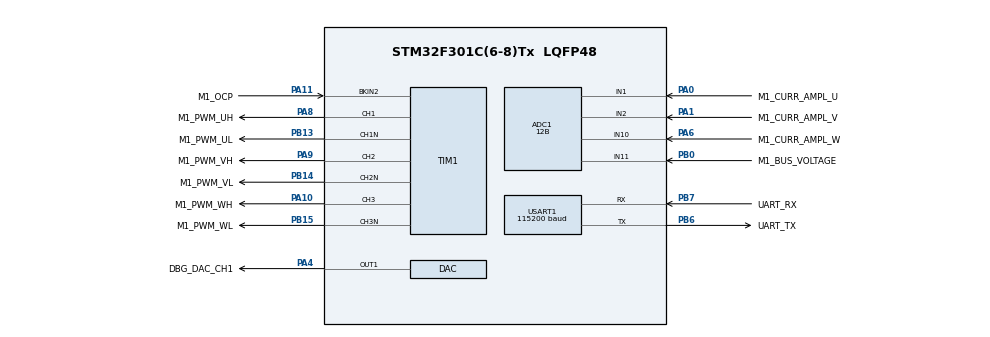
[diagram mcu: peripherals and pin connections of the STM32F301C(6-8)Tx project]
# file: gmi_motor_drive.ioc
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ADC1.Channel-1\#ChannelRegularConversion=ADC_CHANNEL_11
ADC1.Channel-IN1-Single-Ended=ADC_CHANNEL_1
ADC1.Channel-IN10-Single-Ended=ADC_CHANNEL_10
ADC1.Channel-IN11-Single-Ended=ADC_CHANNEL_11
ADC1.Channel-IN2-Single-Ended=ADC_CHANNEL_2
ADC1.ClockPrescaler=ADC_CLOCK_SYNC_PCLK_DIV1
ADC1.ContinuousConvMode=DISABLE
ADC1.DMAContinuousRequests=DISABLE
ADC1.DataAlign=ADC_DATAALIGN_LEFT
ADC1.DiscontinuousConvMode=DISABLE
ADC1.EOCSelection=ADC_EOC_SINGLE_CONV
ADC1.EnableAnalogWatchDog1=false
ADC1.EnableAnalogWatchDog2=false
ADC1.EnableAnalogWatchDog3=false
ADC1.EnableInjectedConversion=ENABLE
ADC1.EnableRegularConversion=ENABLE
ADC1.ExternalTrigConv=ADC_SOFTWARE_START
ADC1.ExternalTrigConvEdge=ADC_EXTERNALTRIGCONVEDGE_NONE
ADC1.ExternalTrigInjecConv=ADC_EXTERNALTRIGINJECCONV_T1_TRGO
ADC1.ExternalTrigInjecConvEdge=ADC_EXTERNALTRIGINJECCONV_EDGE_RISING
ADC1.InjNumberOfConversion=3
ADC1.InjectedChannel-1\#ChannelInjectedConversion=ADC_CHANNEL_1
ADC1.InjectedChannel-2\#ChannelInjectedConversion=ADC_CHANNEL_2
ADC1.InjectedChannel-3\#ChannelInjectedConversion=ADC_CHANNEL_10
ADC1.InjectedConvMode=None
ADC1.InjectedOffset-1\#ChannelInjectedConversion=0
ADC1.InjectedOffset-2\#ChannelInjectedConversion=0
ADC1.InjectedOffset-3\#ChannelInjectedConversion=0
ADC1.InjectedOffsetNumber-1\#ChannelInjectedConversion=ADC_OFFSET_NONE
ADC1.InjectedOffsetNumber-2\#ChannelInjectedConversion=ADC_OFFSET_NONE
ADC1.InjectedOffsetNumber-3\#ChannelInjectedConversion=ADC_OFFSET_NONE
ADC1.InjectedRank-1\#ChannelInjectedConversion=1
ADC1.InjectedRank-2\#ChannelInjectedConversion=2
ADC1.InjectedRank-3\#ChannelInjectedConversion=3
ADC1.InjectedSamplingTime-1\#ChannelInjectedConversion=ADC_SAMPLETIME_19CYCLES_5
ADC1.InjectedSamplingTime-2\#ChannelInjectedConversion=ADC_SAMPLETIME_19CYCLES_5
ADC1.InjectedSamplingTime-3\#ChannelInjectedConversion=ADC_SAMPLETIME_19CYCLES_5
ADC1.LowPowerAutoWait=DISABLE
ADC1.NbrOfConversion=1
ADC1.Offset-1\#ChannelRegularConversion=0
ADC1.OffsetNumber-1\#ChannelRegularConversion=ADC_OFFSET_NONE
ADC1.Overrun=ADC_OVR_DATA_PRESERVED
ADC1.QueueInjectedContext=ENABLE
ADC1.Rank-1\#ChannelRegularConversion=1
ADC1.Resolution=ADC_RESOLUTION_12B
ADC1.SamplingTime-1\#ChannelRegularConversion=ADC_SAMPLETIME_61CYCLES_5
ADC1.ScanConvMode=ADC_SCAN_ENABLE
ADC1.SubFamily=STM32F301x8
ADC1.master=1
DAC.DAC_OutputBuffer-DAC_OUT1=DAC_OUTPUTBUFFER_DISABLE
DAC.DAC_Trigger-DAC_OUT1=DAC_TRIGGER_SOFTWARE
DAC.WaveGeneration-DAC_OUT1=DISABLE
ExtraMW=MotorControl
ExtraMW.MotorControl.Config=MotorControl
ExtraMW.MotorControl.Mode=MotorControl
ExtraMW.MotorControl.Root=MCSDK_v5.4.4-Full/MotorControl
ExtraMW.MotorControl.Template=templates
Mcu.Family=STM32F3
Mcu.Name=STM32F301C(6-8)Tx
Mcu.Package=LQFP48
MotorControl.ADC_1_PERIPH=ADC1
MotorControl.ADC_2_PERIPH=ADC2
MotorControl.ADC_AHBPERIPH=RCC_AHBPeriph_ADC12
MotorControl.ADC_CLOCK_WB_DIV=1
MotorControl.ADC_CLOCK_WB_FREQ=64
MotorControl.ADC_PERIPH=ADC1
MotorControl.ADC_REFERENCE_VOLTAGE=3.30
MotorControl.ALIGNMENT_ANGLE_DEG=90
MotorControl.ALIGNMENT_DURATION=700
MotorControl.AMPLIFICATION_GAIN=7.33
MotorControl.ANGC={0,0,0,0,0,0,0,0}
MotorControl.BEMF_CONSISTENCY_GAIN=64
MotorControl.BEMF_CONSISTENCY_TOL=64
MotorControl.BKIN1_FILTER=0
MotorControl.BKIN2_FILTER=7
MotorControl.BKIN2_MODE=EXT_MODE
MotorControl.BKIN_MODE=NONE
MotorControl.BOARD=CUSTOM
MotorControl.BRKIN2_GPIO_AF=GPIO_AF_2
MotorControl.BRKIN_GPIO_AF=GPIO_AF_12
MotorControl.BUS_VOLTAGE_READING=true
MotorControl.CCMRAM_ENABLED=false
MotorControl.CLOCK_FREQUENCY=CPU_CLK_64_MHZ
MotorControl.CLOCK_SOURCE=INTERNAL
MotorControl.CONSTANT1_D=1347084
MotorControl.CONSTANT1_Q=2435957
MotorControl.CONSTANT2_QD=9081
MotorControl.CORD_BEMF_CONSISTENCY_GAIN=64
MotorControl.CORD_BEMF_CONSISTENCY_TOL=64
MotorControl.CORD_F1=16384
MotorControl.CORD_F2=256
MotorControl.CORD_FIFO_DEPTH_01HZ=64
MotorControl.CORD_FIFO_DEPTH_DPP=64
MotorControl.CORD_GAIN1=-24527
MotorControl.CORD_GAIN2=30710
MotorControl.CORD_MAX_ACCEL_DPPP=301
MotorControl.CORD_MEAS_ERRORS_BEFORE_FAULTS=3
MotorControl.CORD_VARIANCE_THRESHOLD=4
MotorControl.CPU_CLK_64_MHZ=true
MotorControl.CTRBDID=0
MotorControl.CUBE_MX_VER=5.6.1
MotorControl.CURRENT_READING_TOPOLOGY=THREE_SHUNT
MotorControl.CURR_SAMPLING_TIME=61
MotorControl.DAC_EMULATED=false
MotorControl.DAC_FUNCTIONALITY=true
MotorControl.DAC_TIMER_CH1_GPIO_PIN=LL_GPIO_PIN_4
MotorControl.DAC_TIMER_CH1_GPIO_PORT=GPIOA
MotorControl.DAC_TIMER_CH2_GPIO_PIN=LL_GPIO_PIN_0
MotorControl.DAC_TIMER_CH2_GPIO_PORT=GPIOA
MotorControl.DAC_TIMER_SELECTION=TIM3
MotorControl.DC_CURRENT_RS_MEAS=8.75
MotorControl.DEBUG_DAC_CH1=true
MotorControl.DEBUG_DAC_CH2=false
MotorControl.DEFAULT_CONTROL_MODE=STC_TORQUE_MODE
MotorControl.DEFAULT_DAC_CHANNEL_1=MC_PROTOCOL_REG_I_A
MotorControl.DEFAULT_DAC_CHANNEL_2=MC_PROTOCOL_REG_I_B
MotorControl.DEFAULT_DAC_MOTOR=0
MotorControl.DEFAULT_FLUX_COMPONENT=0
MotorControl.DEFAULT_TARGET_SPEED_RPM=1500
MotorControl.DEFAULT_TORQUE_COMPONENT=0
MotorControl.DISSIPATIVE_BRAKE_POLARITY=DOUT_ACTIVE_HIGH
MotorControl.DRIVES_NUMBER_SELECTION=SINGLEDRIVE
MotorControl.EMERGENCY2_STOP_GPIO_PIN=LL_GPIO_PIN_11
MotorControl.EMERGENCY2_STOP_GPIO_PORT=GPIOA
MotorControl.EMERGENCY_STOP_GPIO_PIN=LL_GPIO_PIN_11
MotorControl.EMERGENCY_STOP_GPIO_PORT=GPIOA
MotorControl.ENABLE_SL_ALGO_FROM_PHASE=2
MotorControl.ENCODER_AVAILABLE=false
MotorControl.ENCODER_PPR=400
MotorControl.ENC_AVERAGING_FIFO_DEPTH=16
MotorControl.ENC_A_GPIO_PIN=LL_GPIO_PIN_0
MotorControl.ENC_A_GPIO_PORT=GPIOA
MotorControl.ENC_B_GPIO_PIN=LL_GPIO_PIN_3
MotorControl.ENC_B_GPIO_PORT=GPIOB
MotorControl.ENC_ICx_FILTER=45
MotorControl.ENC_INVERT_SPEED=false
MotorControl.ENC_MEAS_ERRORS_BEFORE_FAULTS=3
MotorControl.ENC_TIMER_REMAPPING=NO_REMAP_TIM2
MotorControl.ENC_TIMER_SELECTION=ENC_TIM2
MotorControl.ENC_USE_CH3=false
MotorControl.EXT_CLOCK_FREQUENCY=INT_RC_OSC
MotorControl.F1=16384
MotorControl.F2=256
MotorControl.FEEDBACK_NET_FILTERING=false
MotorControl.FEED_FORWARD_CURRENT_REG_ENABLING=false
MotorControl.FINAL_I_ALIGNMENT=2838
MotorControl.FLUX_WEAKENING_ENABLING=false
MotorControl.FW_KIDIV=32768
MotorControl.FW_KI_GAIN=5000
MotorControl.FW_KPDIV=32768
MotorControl.FW_KP_GAIN=3000
MotorControl.FW_VOLTAGE_REF=985
MotorControl.GAIN1=-24527
MotorControl.GAIN2=30710
MotorControl.H1_GPIO_PIN=LL_GPIO_PIN_0
MotorControl.H1_GPIO_PORT=GPIOA
MotorControl.H2_GPIO_PIN=LL_GPIO_PIN_3
MotorControl.H2_GPIO_PORT=GPIOB
MotorControl.H3_GPIO_PIN=LL_GPIO_PIN_10
MotorControl.H3_GPIO_PORT=GPIOB
MotorControl.HALL_AVERAGING_FIFO_DEPTH=6
MotorControl.HALL_ICx_FILTER=83
MotorControl.HALL_MEAS_ERRORS_BEFORE_FAULTS=3
MotorControl.HALL_MTPA=false
MotorControl.HALL_PHASE_SHIFT=300
MotorControl.HALL_SENSORS_AVAILABLE=false
MotorControl.HALL_SENSORS_PLACEMENT=DEGREES_120
MotorControl.HALL_TIMER_REMAPPING=NO_REMAP_TIM2
MotorControl.HALL_TIMER_SELECTION=HALL_TIM2
MotorControl.HFI_AMPLITUDE=25
MotorControl.HFI_DC_0_COEFF=0.00146
MotorControl.HFI_DC_1_COEFF=0.002921
MotorControl.HFI_DC_2_COEFF=0.00146
MotorControl.HFI_DC_3_COEFF=1.889033
MotorControl.HFI_DC_4_COEFF=-0.894874
MotorControl.HFI_DEBUG_MODE=false
MotorControl.HFI_FREQUENCY=400
MotorControl.HFI_HIFRAMPLSCAN=25
MotorControl.HFI_HP_ID_0_COEFF=0.855931
MotorControl.HFI_HP_ID_1_COEFF=-1.711861
MotorControl.HFI_HP_ID_2_COEFF=0.855931
MotorControl.HFI_HP_ID_3_COEFF=1.690996
MotorControl.HFI_HP_ID_4_COEFF=-0.732726
MotorControl.HFI_IDH_DELAY=32400
MotorControl.HFI_LOCKFREQ=82
MotorControl.HFI_LP_ID_0_COEFF=0.032106
MotorControl.HFI_LP_ID_1_COEFF=0.064213
MotorControl.HFI_LP_ID_2_COEFF=0.032106
MotorControl.HFI_LP_ID_3_COEFF=1.433067
MotorControl.HFI_LP_ID_4_COEFF=-0.561492
MotorControl.HFI_MAXANGLEDIFF=3640
MotorControl.HFI_MINIMUM_SPEED_RPM=402
MotorControl.HFI_NOTCH_IQD_0_COEFF=0.928286
MotorControl.HFI_NOTCH_IQD_1_COEFF=-1.765705
MotorControl.HFI_NOTCH_IQD_2_COEFF=0.928286
MotorControl.HFI_NOTCH_IQD_3_COEFF=1.765705
MotorControl.HFI_NOTCH_IQD_4_COEFF=-0.856572
MotorControl.HFI_NSDETPOINTSSKIP=10
MotorControl.HFI_NSMAXDETPOINTS=20
MotorControl.HFI_NS_MIN_SAT_DIFF=0
MotorControl.HFI_PID_KIDIV=32768
MotorControl.HFI_PID_KI_DEFAULT=400
MotorControl.HFI_PID_KPDIV=16384
MotorControl.HFI_PID_KP_DEFAULT=800
MotorControl.HFI_PLL_KI_DEFAULT=0.00400
MotorControl.HFI_PLL_KP_DEFAULT=0.00060
MotorControl.HFI_RESTARTTIMESEC=0.1
MotorControl.HFI_RESTART_RPM_TH=(((HFI_STO_RPM_TH)+(STO_HFI_RPM_TH))/2)
MotorControl.HFI_REVERT_DIRECTION=true
MotorControl.HFI_SCANROTATIONSNO=3
MotorControl.HFI_SPD_BUFFER_DEPTH_01HZ=64
MotorControl.HFI_STEPANGLE=3640
MotorControl.HFI_STO_RPM_TH=OBS_MINIMUM_SPEED_RPM
MotorControl.HFI_WAITAFTERNS2=4
MotorControl.HFI_WAITBEFORESN=6
MotorControl.HFI_WAITSYNCH=20
MotorControl.HFI_WAITTRACK=20
MotorControl.HIGH_SIDE_BRAKE_STATE=false
MotorControl.HIGH_SIDE_IDLE_STATE=false
MotorControl.HW_COMPLEMENTED_LOW_SIDE=false
MotorControl.HW_DEAD_TIME_NS=100
MotorControl.HW_OV_CURRENT_PROT_BYPASS=false
MotorControl.ID_DEMAG=-12736
MotorControl.INRUSH_CURRLIMIT_CHANGE_AFTER_MS=2000
MotorControl.INRUSH_CURRLIMIT_ENABLING=true
MotorControl.INRUSH_CURRLIMIT_GPIO_PIN=LL_GPIO_PIN_4
MotorControl.INRUSH_CURRLIMIT_GPIO_PORT=GPIOE
MotorControl.INRUSH_CURR_LIMITER_POLARITY=DOUT_ACTIVE_LOW
MotorControl.INTERNAL_OVERCURRENTPROTECTION=false
MotorControl.INTERNAL_OVERVOLTAGEPROTECTION=false
MotorControl.INT_RC_OSC=true
MotorControl.IPs=NVIC,RCC,SYS,MotorControl,TIM1,ADC1,DAC,USART1
MotorControl.IQMAX=12736
MotorControl.LCD_JOYSTICK_FUNCTIONALITY=false
MotorControl.LCD_MODE=LCD_FULL
MotorControl.LDLQ_RATIO=0.553
MotorControl.LOW_SIDE_BRAKE_STATE=false
MotorControl.LOW_SIDE_IDLE_STATE=false
MotorControl.LOW_SIDE_SIGNALS_ENABLING=LS_PWM_TIMER
MotorControl.LS=0.128915
MotorControl.MAX_APPLICATION_SPEED=2000
MotorControl.MAX_MODULATION_98_PER_CENT=true
MotorControl.MAX_MODULATION_INDEX=MAX_MODULATION_98_PER_CENT
MotorControl.MCU=STM32F302R8
MotorControl.MCU_TYPE=STM32F302X8
MotorControl.MC_WORKBENCH_VERSION=5.4.4.20160
MotorControl.MEAS_ERRORS_BEFORE_FAULTS=3
MotorControl.MIN_APPLICATION_SPEED=0
MotorControl.MOTOR_MAX_SPEED_RPM=2000
MotorControl.MOTOR_TYPE=PMSM
MotorControl.MOTOR_VOLTAGE_CONSTANT=55.5
MotorControl.MTPA_ENABLING=false
MotorControl.NB_CONSECUTIVE_TESTS=2
MotorControl.NOMINAL_BUS_VOLTAGE_V=101
MotorControl.NOMINAL_CURRENT=12736
MotorControl.OBS_MEAS_ERRORS_BEFORE_FAULTS=3
MotorControl.OBS_MINIMUM_SPEED_RPM=350
MotorControl.OCPA_INVERTINGINPUT=COMPX_InvertingInput_VREF
MotorControl.OCPA_INVERTINGINPUT_GPIO_PIN=LL_GPIO_PIN_4
MotorControl.OCPA_INVERTINGINPUT_GPIO_PORT=GPIOA
MotorControl.OCPA_INVERTINGINPUT_MODE=INT_MODE
MotorControl.OCPA_NONINVERTINGINPUT=COMP2_NonInvertingInput_PA7
MotorControl.OCPA_NONINVERTINGINPUT_GPIO_PIN=LL_GPIO_PIN_7
MotorControl.OCPA_NONINVERTINGINPUT_GPIO_PORT=GPIOA
MotorControl.OCPA_OUTPUT=COMP_Output_TIM1BKIN2
MotorControl.OCPA_OUTPUTPOL=COMP_OutputPol_NonInverted
MotorControl.OCPA_OUTPUT_GPIO_AF=GPIO_AF_8
MotorControl.OCPA_OUTPUT_GPIO_PIN=LL_GPIO_PIN_2
MotorControl.OCPA_OUTPUT_GPIO_PORT=GPIOA
MotorControl.OCPA_OUTPUT_MODE=INT_MODE
MotorControl.OCPA_SELECTION=COMP2
MotorControl.OCPB_INVERTINGINPUT=COMPX_InvertingInput_VREF
MotorControl.OCPB_INVERTINGINPUT_GPIO_PIN=LL_GPIO_PIN_4
MotorControl.OCPB_INVERTINGINPUT_GPIO_PORT=GPIOA
MotorControl.OCPB_INVERTINGINPUT_MODE=INT_MODE
MotorControl.OCPB_NONINVERTINGINPUT=COMP4_NonInvertingInput_PB0
MotorControl.OCPB_NONINVERTINGINPUT_GPIO_PIN=LL_GPIO_PIN_0
MotorControl.OCPB_NONINVERTINGINPUT_GPIO_PORT=GPIOB
MotorControl.OCPB_OUTPUT=COMP_Output_TIM1BKIN2
MotorControl.OCPB_OUTPUTPOL=COMP_OutputPol_NonInverted
MotorControl.OCPB_OUTPUT_GPIO_AF=GPIO_AF_8
MotorControl.OCPB_OUTPUT_GPIO_PIN=LL_GPIO_PIN_1
MotorControl.OCPB_OUTPUT_GPIO_PORT=GPIOB
MotorControl.OCPB_OUTPUT_MODE=INT_MODE
MotorControl.OCPB_SELECTION=COMP4
MotorControl.OCPC_INVERTINGINPUT=COMPX_InvertingInput_VREF
MotorControl.OCPC_INVERTINGINPUT_GPIO_PIN=LL_GPIO_PIN_4
MotorControl.OCPC_INVERTINGINPUT_GPIO_PORT=GPIOA
MotorControl.OCPC_INVERTINGINPUT_MODE=INT_MODE
MotorControl.OCPC_NONINVERTINGINPUT=COMP6_NonInvertingInput_PB11
MotorControl.OCPC_NONINVERTINGINPUT_GPIO_PIN=LL_GPIO_PIN_11
MotorControl.OCPC_NONINVERTINGINPUT_GPIO_PORT=GPIOB
MotorControl.OCPC_OUTPUT=COMP_Output_TIM1BKIN2
MotorControl.OCPC_OUTPUTPOL=COMP_OutputPol_NonInverted
MotorControl.OCPC_OUTPUT_GPIO_AF=GPIO_AF_8
MotorControl.OCPC_OUTPUT_GPIO_PIN=LL_GPIO_PIN_10
MotorControl.OCPC_OUTPUT_GPIO_PORT=GPIOA
MotorControl.OCPC_OUTPUT_MODE=INT_MODE
MotorControl.OCPC_SELECTION=COMP6
MotorControl.OCPREF=23830
MotorControl.OCP_COMP_THRESHOLD=1.65
MotorControl.OCP_FILTER=COMP_Mode_HighSpeed
MotorControl.OCP_INVERTINGINPUT=COMPX_InvertingInput_VREF
MotorControl.OCP_INVERTINGINPUT_GPIO_PIN=LL_GPIO_PIN_4
MotorControl.OCP_INVERTINGINPUT_GPIO_PORT=GPIOA
MotorControl.OCP_INVERTINGINPUT_MODE=INT_MODE
MotorControl.OCP_NONINVERTINGINPUT=COMP2_NonInvertingInput_PA7
MotorControl.OCP_NONINVERTINGINPUT_GPIO_PIN=LL_GPIO_PIN_7
MotorControl.OCP_NONINVERTINGINPUT_GPIO_PORT=GPIOA
MotorControl.OCP_OUTPUT=COMP_Output_TIM1BKIN2
MotorControl.OCP_OUTPUTPOL=COMP_OutputPol_NonInverted
MotorControl.OCP_OUTPUT_GPIO_AF=GPIO_AF_8
MotorControl.OCP_OUTPUT_GPIO_PIN=LL_GPIO_PIN_2
MotorControl.OCP_OUTPUT_GPIO_PORT=GPIOA
MotorControl.OCP_OUTPUT_MODE=INT_MODE
MotorControl.OCP_SELECTION=COMP2
MotorControl.OFST={0,0,0,0,0,0,0,0}
MotorControl.ON_OVER_VOLTAGE=TURN_OFF_PWM
MotorControl.OPAMP1_INVERTINGINPUT=OPAMP1_InvertingInput_PGA
MotorControl.OPAMP1_INVERTINGINPUT_GPIO_PIN=LL_GPIO_PIN_3
MotorControl.OPAMP1_INVERTINGINPUT_GPIO_PORT=GPIOA
MotorControl.OPAMP1_INVERTINGINPUT_MODE=INT_MODE
MotorControl.OPAMP1_NONINVERTINGINPUT_PHA=OPAMP1_NonInvertingInput_PA1
MotorControl.OPAMP1_NONINVERTINGINPUT_PHA_GPIO_PIN=LL_GPIO_PIN_1
MotorControl.OPAMP1_NONINVERTINGINPUT_PHA_GPIO_PORT=GPIOA
MotorControl.OPAMP1_NONINVERTINGINPUT_PHB=OPAMP1_NonInvertingInput_PA7
MotorControl.OPAMP1_NONINVERTINGINPUT_PHB_GPIO_PIN=LL_GPIO_PIN_7
MotorControl.OPAMP1_NONINVERTINGINPUT_PHB_GPIO_PORT=GPIOA
MotorControl.OPAMP1_OUT_GPIO_PIN=LL_GPIO_PIN_2
MotorControl.OPAMP1_OUT_GPIO_PORT=GPIOA
MotorControl.OPAMP1_SELECTION=OPAMP1
MotorControl.OPAMP2_INVERTINGINPUT=OPAMP2_InvertingInput_PGA
MotorControl.OPAMP2_INVERTINGINPUT_GPIO_PIN=LL_GPIO_PIN_5
MotorControl.OPAMP2_INVERTINGINPUT_GPIO_PORT=GPIOC
MotorControl.OPAMP2_INVERTINGINPUT_MODE=INT_MODE
MotorControl.OPAMP2_NONINVERTINGINPUT_PHA=OPAMP2_NonInvertingInput_PB14
MotorControl.OPAMP2_NONINVERTINGINPUT_PHA_GPIO_PIN=LL_GPIO_PIN_14
MotorControl.OPAMP2_NONINVERTINGINPUT_PHA_GPIO_PORT=GPIOB
MotorControl.OPAMP2_NONINVERTINGINPUT_PHB=OPAMP2_NonInvertingInput_PA7
MotorControl.OPAMP2_NONINVERTINGINPUT_PHB_GPIO_PIN=LL_GPIO_PIN_7
MotorControl.OPAMP2_NONINVERTINGINPUT_PHB_GPIO_PORT=GPIOA
MotorControl.OPAMP2_NONINVERTINGINPUT_PHC=OPAMP2_NonInvertingInput_PB14
MotorControl.OPAMP2_NONINVERTINGINPUT_PHC_GPIO_PIN=LL_GPIO_PIN_14
MotorControl.OPAMP2_NONINVERTINGINPUT_PHC_GPIO_PORT=GPIOB
MotorControl.OPAMP2_OUT_GPIO_PIN=LL_GPIO_PIN_6
MotorControl.OPAMP2_OUT_GPIO_PORT=GPIOA
MotorControl.OPAMP2_SELECTION=OPAMP2
MotorControl.OPAMP3_INVERTINGINPUT=OPAMP1_InvertingInput_PGA
MotorControl.OPAMP3_INVERTINGINPUT_GPIO_PIN=LL_GPIO_PIN_0
MotorControl.OPAMP3_INVERTINGINPUT_GPIO_PORT=GPIOA
MotorControl.OPAMP3_INVERTINGINPUT_MODE=INT_MODE
MotorControl.OPAMP3_SELECTION=OPAMP1
MotorControl.OPAMP_INVERTINGINPUT=OPAMP1_InvertingInput_PGA
MotorControl.OPAMP_INVERTINGINPUT_GPIO_PIN=LL_GPIO_PIN_3
MotorControl.OPAMP_INVERTINGINPUT_GPIO_PORT=GPIOA
MotorControl.OPAMP_INVERTINGINPUT_MODE=INT_MODE
MotorControl.OPAMP_NONINVERTINGINPUT=OPAMP1_NonInvertingInput_PA7
MotorControl.OPAMP_NONINVERTINGINPUT_GPIO_PIN=LL_GPIO_PIN_7
MotorControl.OPAMP_NONINVERTINGINPUT_GPIO_PORT=GPIOA
MotorControl.OPAMP_OUT_GPIO_PIN=LL_GPIO_PIN_2
MotorControl.OPAMP_OUT_GPIO_PORT=GPIOA
MotorControl.OPAMP_PGACONNECT=OPAMP_PGAConnect_No
MotorControl.OPAMP_PGAGAIN=OPAMP_OPAMP_PGAGain_2
MotorControl.OPAMP_SELECTION=OPAMP1
MotorControl.OPAMP_TYPE_GAIN=INTERNAL
MotorControl.OPEN_LOOP_FOC=false
MotorControl.OPEN_LOOP_K=44
MotorControl.OPEN_LOOP_OFF=4400
MotorControl.OPEN_LOOP_SPEED_RAMP_DURATION_MS=1000
MotorControl.OPEN_LOOP_SPEED_RPM=100
MotorControl.OPEN_LOOP_VF=false
MotorControl.OPEN_LOOP_VOLTAGE_d=6000
MotorControl.OVERCURR_FEEDBACK_POLARITY=EMSTOP2_ACTIVE_LOW
MotorControl.OVERCURR_PROTECTION_HW_DISABLING=DOUT_ACTIVE_HIGH
MotorControl.OVPREF=23830
MotorControl.OVP_FILTER=COMP_Mode_HighSpeed
MotorControl.OVP_INVERTINGINPUT=COMPX_InvertingInput_VREF
MotorControl.OVP_INVERTINGINPUT_GPIO_PIN=LL_GPIO_PIN_4
MotorControl.OVP_INVERTINGINPUT_GPIO_PORT=GPIOA
MotorControl.OVP_INVERTINGINPUT_MODE=INT_MODE
MotorControl.OVP_NONINVERTINGINPUT=COMP2_NonInvertingInput_PA7
MotorControl.OVP_NONINVERTINGINPUT_GPIO_PIN=LL_GPIO_PIN_7
MotorControl.OVP_NONINVERTINGINPUT_GPIO_PORT=GPIOA
MotorControl.OVP_OUTPUT=COMP_Output_TIM1BKIN
MotorControl.OVP_OUTPUTPOL=COMP_OutputPol_NonInverted
MotorControl.OVP_OUTPUT_GPIO_AF=GPIO_AF_8
MotorControl.OVP_OUTPUT_GPIO_PIN=LL_GPIO_PIN_2
MotorControl.OVP_OUTPUT_GPIO_PORT=GPIOA
MotorControl.OVP_OUTPUT_MODE=INT_MODE
MotorControl.OVP_SELECTION=COMP2
MotorControl.OV_CURR_BYPASS_GPIO_PIN=LL_GPIO_PIN_5
MotorControl.OV_CURR_BYPASS_GPIO_PORT=GPIOE
MotorControl.OV_TEMPERATURE_HYSTERESIS_C=10
MotorControl.OV_TEMPERATURE_PROT_ENABLING=false
MotorControl.OV_TEMPERATURE_THRESHOLD_C=70
MotorControl.OV_VOLTAGE_PROT_ENABLING=true
MotorControl.OV_VOLTAGE_THRESHOLD_V=160
MotorControl.PHASE1_DURATION=4000
MotorControl.PHASE1_FINAL_CURRENT=8733
MotorControl.PHASE1_FINAL_SPEED_RPM=0
MotorControl.PHASE2_DURATION=6000
MotorControl.PHASE2_FINAL_CURRENT=8733
MotorControl.PHASE2_FINAL_SPEED_RPM=1000
MotorControl.PHASE3_DURATION=0
MotorControl.PHASE3_FINAL_CURRENT=1455
MotorControl.PHASE3_FINAL_SPEED_RPM=1000
MotorControl.PHASE4_DURATION=0
MotorControl.PHASE4_FINAL_CURRENT=1455
MotorControl.PHASE4_FINAL_SPEED_RPM=1000
MotorControl.PHASE5_DURATION=0
MotorControl.PHASE5_FINAL_CURRENT=1455
MotorControl.PHASE5_FINAL_SPEED_RPM=2000
MotorControl.PHASE_CURRENTS_ADC=ADC1_2
MotorControl.PHASE_CURRENTS_CHANNEL=ADC_CHANNEL_9
MotorControl.PHASE_CURRENTS_GPIO_PIN=LL_GPIO_PIN_0
MotorControl.PHASE_CURRENTS_GPIO_PORT=GPIOA
MotorControl.PHASE_UH_GPIO_AF=GPIO_AF_6
MotorControl.PHASE_UH_GPIO_PIN=LL_GPIO_PIN_8
MotorControl.PHASE_UH_GPIO_PORT=GPIOA
MotorControl.PHASE_UH_POLARITY=H_ACTIVE_HIGH
MotorControl.PHASE_UL_GPIO_AF=GPIO_AF_6
MotorControl.PHASE_UL_GPIO_PIN=LL_GPIO_PIN_13
MotorControl.PHASE_UL_GPIO_PORT=GPIOB
MotorControl.PHASE_UL_POLARITY=L_ACTIVE_HIGH
MotorControl.PHASE_U_CURR_ADC=ADC1
MotorControl.PHASE_U_CURR_CHANNEL=ADC_CHANNEL_1
MotorControl.PHASE_U_GPIO_PIN=LL_GPIO_PIN_0
MotorControl.PHASE_U_GPIO_PORT=GPIOA
MotorControl.PHASE_VH_GPIO_AF=GPIO_AF_6
MotorControl.PHASE_VH_GPIO_PIN=LL_GPIO_PIN_9
MotorControl.PHASE_VH_GPIO_PORT=GPIOA
MotorControl.PHASE_VH_POLARITY=H_ACTIVE_HIGH
MotorControl.PHASE_VL_GPIO_AF=GPIO_AF_6
MotorControl.PHASE_VL_GPIO_PIN=LL_GPIO_PIN_14
MotorControl.PHASE_VL_GPIO_PORT=GPIOB
MotorControl.PHASE_VL_POLARITY=L_ACTIVE_HIGH
MotorControl.PHASE_V_CURR_ADC=ADC1
MotorControl.PHASE_V_CURR_CHANNEL=ADC_CHANNEL_2
MotorControl.PHASE_V_GPIO_PIN=LL_GPIO_PIN_1
MotorControl.PHASE_V_GPIO_PORT=GPIOA
MotorControl.PHASE_WH_GPIO_AF=GPIO_AF_6
MotorControl.PHASE_WH_GPIO_PIN=LL_GPIO_PIN_10
MotorControl.PHASE_WH_GPIO_PORT=GPIOA
MotorControl.PHASE_WH_POLARITY=H_ACTIVE_HIGH
MotorControl.PHASE_WL_GPIO_AF=GPIO_AF_4
MotorControl.PHASE_WL_GPIO_PIN=LL_GPIO_PIN_15
MotorControl.PHASE_WL_GPIO_PORT=GPIOB
MotorControl.PHASE_WL_POLARITY=L_ACTIVE_HIGH
MotorControl.PHASE_W_CURR_ADC=ADC1
MotorControl.PHASE_W_CURR_CHANNEL=ADC_CHANNEL_10
MotorControl.PHASE_W_GPIO_PIN=LL_GPIO_PIN_6
MotorControl.PHASE_W_GPIO_PORT=GPIOA
MotorControl.PID_FLUX_KD_DEFAULT=100
MotorControl.PID_FLUX_KI_DEFAULT=3743
MotorControl.PID_FLUX_KP_DEFAULT=2034
MotorControl.PID_SPEED_KD_DEFAULT=0
MotorControl.PID_SPEED_KI_DEFAULT=1000
MotorControl.PID_SPEED_KP_DEFAULT=15000
MotorControl.PID_TORQUE_KD_DEFAULT=100
MotorControl.PID_TORQUE_KI_DEFAULT=3743
MotorControl.PID_TORQUE_KP_DEFAULT=3678
MotorControl.PLL_KI_GAIN=58
MotorControl.PLL_KP_GAIN=665
MotorControl.POLE_PAIR_NUM=5
MotorControl.POSITION_CTRL_ENABLING=false
MotorControl.PWBDID=0
MotorControl.PWM_FREQUENCY=8000
MotorControl.PWM_TIMER_REMAPPING=PWM_NO_REMAP
MotorControl.PWM_TIMER_SELECTION=PWM_TIM1
MotorControl.REGCONVADC=ADC1
MotorControl.REGULATION_EXECUTION_RATE=1
MotorControl.RS=4.10
MotorControl.RSHUNT=0.01000
MotorControl.RTOS=NONE
MotorControl.R_BRAKE_GPIO_PIN=LL_GPIO_PIN_5
MotorControl.R_BRAKE_GPIO_PORT=GPIOE
MotorControl.R_BRAKE_SWITCH_OFF_THRES_V=128
MotorControl.SEGDIV=0
MotorControl.SERIAL_COMMUNICATION=true
MotorControl.SERIAL_COM_CHANNEL1=MC_PROTOCOL_REG_I_A
MotorControl.SERIAL_COM_CHANNEL2=MC_PROTOCOL_REG_I_A
MotorControl.SERIAL_COM_MODE=COM_BIDIRECTIONAL
MotorControl.SERIAL_COM_MOTOR=0
MotorControl.SHARED_SIGNAL_ENABLE=false
MotorControl.SINGLEDRIVE=true
MotorControl.SPD_DIFFERENTIAL_TERM_ENABLING=false
MotorControl.SPEED_BAND_LOWER_LIMIT=15
MotorControl.SPEED_BAND_UPPER_LIMIT=17
MotorControl.SPEED_FEEDBACK_CHECK=true
MotorControl.SPEED_LOOP_FREQUENCY_HZ=1000
MotorControl.SPEED_SENSOR_SELECTION=STATE_OBSERVER_PLL
MotorControl.SP_KDDIV=16
MotorControl.SP_KIDIV=16384
MotorControl.SP_KPDIV=16
MotorControl.STARTING_ANGLE_DEG=90
MotorControl.START_STOP_BTN=false
MotorControl.START_STOP_GPIO_PIN=LL_GPIO_PIN_6
MotorControl.START_STOP_GPIO_PORT=GPIOE
MotorControl.START_STOP_POLARITY=DIN_ACTIVE_LOW
MotorControl.START_STOP_POLARITY_EDGE=GPIO_NOPULL
MotorControl.STATE_OBSERVER_PLL=true
MotorControl.STM32F302X8=true
MotorControl.STO_FIFO_DEPTH_01HZ=64
MotorControl.STO_FIFO_DEPTH_DPP=64
MotorControl.STO_HFI_RPM_TH=460
MotorControl.SW_DEADTIME_NS=1500
MotorControl.SW_OV_CURRENT_PROT_ENABLING=true
MotorControl.T0_C=25
MotorControl.TEMPERATURE_READING=false
MotorControl.TEMP_ADC_SAMPLING_TIME=61
MotorControl.TEMP_FDBK_ADC=ADC1
MotorControl.TEMP_FDBK_CHANNEL=ADC_CHANNEL_5
MotorControl.TEMP_FDBK_GPIO_PIN=LL_GPIO_PIN_4
MotorControl.TEMP_FDBK_GPIO_PORT=GPIOA
MotorControl.TFDIFFERENTIAL_TERM_ENABLING=false
MotorControl.TF_KDDIV=8192
MotorControl.TF_KIDIV=16384
MotorControl.TF_KPDIV=64
MotorControl.THREE_SHUNT=true
MotorControl.TNOISE_NS=2500
MotorControl.TRANSITION_DURATION=25
MotorControl.TRISE_NS=2500
MotorControl.T_MAX=90
MotorControl.UD_VOLTAGE_THRESHOLD_V=60
MotorControl.USART_REMAPPING=NO_REMAP_USART1
MotorControl.USART_RX_GPIO_PIN=LL_GPIO_PIN_7
MotorControl.USART_RX_GPIO_PORT=GPIOB
MotorControl.USART_SELECTION=USE_USART1
MotorControl.USART_SPEED=115200
MotorControl.USART_TX_GPIO_PIN=LL_GPIO_PIN_6
MotorControl.USART_TX_GPIO_PORT=GPIOB
MotorControl.USE_3OPAMPS=false
MotorControl.USE_INTERNAL_OPAMP=false
MotorControl.UV_VOLTAGE_PROT_ENABLING=true
MotorControl.V0_V=0.464
MotorControl.VARIANCE_THRESHOLD=0.1
MotorControl.VBUS_ADC=ADC1
MotorControl.VBUS_ADC_SAMPLING_TIME=61
MotorControl.VBUS_CHANNEL=ADC_CHANNEL_11
MotorControl.VBUS_GPIO_PIN=LL_GPIO_PIN_0
MotorControl.VBUS_GPIO_PORT=GPIOB
MotorControl.VBUS_PARTITIONING_FACTOR=0.0034
MotorControl.WB_to_Mx_template_version=20-04-17
MotorControl.WB_to_Mx_version=1.1.0
MotorControl.dV_dT=0.025
NVIC.ADC1_IRQn=true\:2\:0\:true\:true\:false\:3\:true\:false
NVIC.PriorityGroup=NVIC_PRIORITYGROUP_3
NVIC.TIM1_BRK_TIM15_IRQn=true\:4\:1\:true\:true\:false\:1\:true\:false
NVIC.TIM1_UP_TIM16_IRQn=true\:0\:0\:false\:true\:false\:2\:true\:false
NVIC.USART1_IRQn=true\:3\:1\:true\:true\:false\:4\:true\:false
PA0.GPIO_Label=M1_CURR_AMPL_U
PA0.Mode=IN1-Single-Ended
PA0.Signal=ADC1_IN1
PA1.GPIO_Label=M1_CURR_AMPL_V
PA1.Mode=IN2-Single-Ended
PA1.Signal=ADC1_IN2
PA10.GPIO_Label=M1_PWM_WH
PA10.GPIO_PuPd=GPIO_PULLDOWN
PA10.GPIO_Speed=GPIO_SPEED_FREQ_HIGH
PA10.Signal=S_TIM1_CH3
PA11.GPIO_Label=M1_OCP
PA11.GPIO_PuPd=GPIO_PULLUP
PA11.Mode=Activate-Break-Input-2
PA11.Signal=TIM1_BKIN2
PA4.GPIO_Label=DBG_DAC_CH1
PA4.Signal=COMP_DAC1_group
PA6.GPIO_Label=M1_CURR_AMPL_W
PA6.Signal=ADCx_IN10
PA8.GPIO_Label=M1_PWM_UH
PA8.GPIO_PuPd=GPIO_PULLDOWN
PA8.GPIO_Speed=GPIO_SPEED_FREQ_HIGH
PA8.Signal=S_TIM1_CH1
PA9.GPIO_Label=M1_PWM_VH
PA9.GPIO_PuPd=GPIO_PULLDOWN
PA9.GPIO_Speed=GPIO_SPEED_FREQ_HIGH
PA9.Signal=S_TIM1_CH2
PB0.GPIO_Label=M1_BUS_VOLTAGE
PB0.Mode=IN11-Single-Ended
PB0.Signal=ADC1_IN11
PB13.GPIO_Label=M1_PWM_UL
PB13.GPIO_PuPd=GPIO_PULLDOWN
PB13.GPIO_Speed=GPIO_SPEED_FREQ_HIGH
PB13.Mode=PWM Generation1 CH1 CH1N
PB13.Signal=TIM1_CH1N
PB14.GPIO_Label=M1_PWM_VL
PB14.GPIO_PuPd=GPIO_PULLDOWN
PB14.GPIO_Speed=GPIO_SPEED_FREQ_HIGH
PB14.Mode=PWM Generation2 CH2 CH2N
PB14.Signal=TIM1_CH2N
PB15.GPIO_Label=M1_PWM_WL
PB15.GPIO_PuPd=GPIO_PULLDOWN
PB15.GPIO_Speed=GPIO_SPEED_FREQ_HIGH
PB15.Mode=PWM Generation3 CH3 CH3N
PB15.Signal=TIM1_CH3N
PB6.GPIO_Label=UART_TX
PB6.GPIO_PuPd=GPIO_NOPULL
PB6.GPIO_Speed=GPIO_SPEED_FREQ_LOW
PB6.Mode=Asynchronous
PB6.Signal=USART1_TX
PB7.GPIO_Label=UART_RX
PB7.GPIO_PuPd=GPIO_NOPULL
PB7.GPIO_Speed=GPIO_SPEED_FREQ_LOW
PB7.Mode=Asynchronous
PB7.Signal=USART1_RX
ProjectManager.HeapSize=0x200
ProjectManager.StackSize=0x400
ProjectManager.TargetToolchain=EWARM V8
RCC.AHBFreq_Value=64000000
RCC.APB1CLKDivider=RCC_HCLK_DIV2
RCC.APB1Freq_Value=32000000
RCC.APB1TimFreq_Value=64000000
RCC.APB2Freq_Value=64000000
RCC.APB2TimFreq_Value=64000000
RCC.CortexFreq_Value=64000000
RCC.FLatency=FLASH_LATENCY_2
RCC.HCLKFreq_Value=64000000
RCC.HSE_VALUE=8000000
RCC.HSI_VALUE=8000000
RCC.LSE_VALUE=32768
RCC.PLLMUL=RCC_PLL_MUL16
RCC.SYSCLKFreq_VALUE=64000000
RCC.SYSCLKSourceVirtual=RCC_SYSCLKSOURCE_PLLCLK
SH.ADCx_IN10.0=ADC1_IN10,IN10-Single-Ended
SH.COMP_DAC1_group.0=DAC_OUT1,DAC_OUT1
SH.S_TIM1_CH1.0=TIM1_CH1,PWM Generation1 CH1 CH1N
SH.S_TIM1_CH2.0=TIM1_CH2,PWM Generation2 CH2 CH2N
SH.S_TIM1_CH3.0=TIM1_CH3,PWM Generation3 CH3 CH3N
TIM1.AutoReloadPreload=TIM_AUTORELOAD_PRELOAD_DISABLE
TIM1.AutomaticOutput=TIM_AUTOMATICOUTPUT_DISABLE
TIM1.Break2Filter=0
TIM1.Break2Polarity=TIM_BREAK2POLARITY_LOW
TIM1.Break2State=TIM_BREAK2_ENABLE
TIM1.BreakFilter=0
TIM1.BreakPolarity=TIM_BREAKPOLARITY_HIGH
TIM1.BreakState=TIM_BREAK_DISABLE
TIM1.Channel-PWM\ Generation1\ CH1\ CH1N=TIM_CHANNEL_1
TIM1.Channel-PWM\ Generation2\ CH2\ CH2N=TIM_CHANNEL_2
TIM1.Channel-PWM\ Generation3\ CH3\ CH3N=TIM_CHANNEL_3
TIM1.Channel-PWM\ Generation4\ No\ Output=TIM_CHANNEL_4
TIM1.ClearInputSource=TIM_CLEARINPUTSOURCE_NONE
TIM1.ClockDivision=TIM_CLOCKDIVISION_DIV2
TIM1.CounterMode=TIM_COUNTERMODE_CENTERALIGNED1
TIM1.DeadTime=((DEAD_TIME_COUNTS) / 2)
TIM1.LockLevel=TIM_LOCKLEVEL_1
TIM1.OC1Preload_PWM=ENABLE
TIM1.OC2Preload_PWM=ENABLE
TIM1.OC3Preload_PWM=ENABLE
TIM1.OC4Preload_PWM=ENABLE
TIM1.OCFastMode_PWM-PWM\ Generation1\ CH1\ CH1N=TIM_OCFAST_DISABLE
TIM1.OCFastMode_PWM-PWM\ Generation2\ CH2\ CH2N=TIM_OCFAST_DISABLE
TIM1.OCFastMode_PWM-PWM\ Generation3\ CH3\ CH3N=TIM_OCFAST_DISABLE
TIM1.OCFastMode_PWM-PWM\ Generation4\ No\ Output=TIM_OCFAST_DISABLE
TIM1.OCIdleState_1=TIM_OCIDLESTATE_RESET
TIM1.OCIdleState_2=TIM_OCIDLESTATE_RESET
TIM1.OCIdleState_3=TIM_OCIDLESTATE_RESET
TIM1.OCIdleState_4=TIM_OCIDLESTATE_RESET
TIM1.OCMode_PWM-PWM\ Generation1\ CH1\ CH1N=TIM_OCMODE_PWM1
TIM1.OCMode_PWM-PWM\ Generation2\ CH2\ CH2N=TIM_OCMODE_PWM1
TIM1.OCMode_PWM-PWM\ Generation3\ CH3\ CH3N=TIM_OCMODE_PWM1
TIM1.OCMode_PWM-PWM\ Generation4\ No\ Output=TIM_OCMODE_PWM2
TIM1.OCNIdleState_1=TIM_OCNIDLESTATE_RESET
TIM1.OCNIdleState_2=TIM_OCNIDLESTATE_RESET
TIM1.OCNIdleState_3=TIM_OCNIDLESTATE_RESET
TIM1.OCNPolarity_1=TIM_OCNPOLARITY_HIGH
TIM1.OCNPolarity_2=TIM_OCNPOLARITY_HIGH
TIM1.OCNPolarity_3=TIM_OCNPOLARITY_HIGH
TIM1.OCPolarity_1=TIM_OCPOLARITY_HIGH
TIM1.OCPolarity_2=TIM_OCPOLARITY_HIGH
TIM1.OCPolarity_3=TIM_OCPOLARITY_HIGH
TIM1.OCPolarity_4=TIM_OCPOLARITY_HIGH
TIM1.OffStateIDLEMode=TIM_OSSI_ENABLE
TIM1.OffStateRunMode=TIM_OSSR_ENABLE
TIM1.Period=((PWM_PERIOD_CYCLES) / 2)
TIM1.Prescaler=((TIM_CLOCK_DIVIDER) - 1)
TIM1.Pulse-PWM\ Generation1\ CH1\ CH1N=0
TIM1.Pulse-PWM\ Generation2\ CH2\ CH2N=0
TIM1.Pulse-PWM\ Generation3\ CH3\ CH3N=0
TIM1.Pulse-PWM\ Generation4\ No\ Output=(((PWM_PERIOD_CYCLES) / 2) - (HTMIN))
TIM1.RepetitionCounter=(REP_COUNTER)
TIM1.TIM_MasterOutputTrigger=TIM_TRGO_OC4REF
TIM1.TIM_MasterOutputTrigger2=TIM_TRGO2_RESET
TIM1.TIM_MasterSlaveMode=TIM_MASTERSLAVEMODE_DISABLE
TIM1.TIM_SlaveMode=TIM_SLAVEMODE_TRIGGER
USART1.AutoBaudRateEnableParam=UART_ADVFEATURE_AUTOBAUDRATE_DISABLE
USART1.BaudRate=115200
USART1.DMADisableonRxErrorParam=ADVFEATURE_DMA_ENABLEONRXERROR
USART1.DataInvertParam=ADVFEATURE_DATAINV_DISABLE
USART1.MSBFirstParam=ADVFEATURE_MSBFIRST_DISABLE
USART1.Mode=MODE_TX_RX
USART1.OneBitSampling=UART_ONE_BIT_SAMPLE_DISABLE
USART1.OverSampling=UART_OVERSAMPLING_16
USART1.OverrunDisableParam=ADVFEATURE_OVERRUN_ENABLE
USART1.Parity=PARITY_NONE
USART1.RxPinLevelInvertParam=ADVFEATURE_RXINV_DISABLE
USART1.StopBits=STOPBITS_1
USART1.SwapParam=ADVFEATURE_SWAP_DISABLE
USART1.TxPinLevelInvertParam=ADVFEATURE_TXINV_DISABLE
USART1.VirtualMode-Asynchronous=VM_ASYNC
USART1.WordLength=WORDLENGTH_8B
VP_MotorControl_MC_ENABLED.Mode=Enabled
VP_TIM1_VS_ClockSourceITR.Mode=TriggerSource_ITR1
VP_TIM1_VS_ControllerModeTrigger.Mode=Trigger Mode
VP_TIM1_VS_no_output4.Mode=PWM Generation4 No Output
board=custom

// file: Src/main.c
/* USER CODE BEGIN Header */
/**
  ******************************************************************************
  * @file           : main.c
  * @brief          : Main program body
  ******************************************************************************
  * @attention
  *
  * <h2><center>&copy; Copyright (c) 2020 STMicroelectronics.
  * All rights reserved.</center></h2>
  *
  * This software component is licensed by ST under Ultimate Liberty license
  * SLA0044, the "License"; You may not use this file except in compliance with
  * the License. You may obtain a copy of the License at:
  *                             www.st.com/SLA0044
  *
  ******************************************************************************
  */
/* USER CODE END Header */

#include "main.h"
#include "motorcontrol.h"

void SystemClock_Config(void);
static void MX_GPIO_Init(void);
static void MX_ADC1_Init(void);
static void MX_DAC_Init(void);
static void MX_TIM1_Init(void);
static void MX_USART1_UART_Init(void);
static void MX_NVIC_Init(void);

int main(void)
{
  /* USER CODE BEGIN 1 */
  // Regen disable. Prevent speed controller from commanding negative Iq which would cause regen. Good to include in early testing.
  PIDSpeedHandle_M1.hLowerOutputLimit=0;
  PIDSpeedHandle_M1.wLowerIntegralLimit=0;
  /* USER CODE END 1 */

  /* MCU Configuration--------------------------------------------------------*/

  /* Reset of all peripherals, Initializes the Flash interface and the Systick. */
  HAL_Init();

  /* USER CODE BEGIN Init */

  // 2500ms delay is our workaround for the in rush bug we have discovered 20200715.
  // - Very minor issue we can resolve with our final code but for now,
  // -- just delay the whole code startup to allow the inrush to function as needed.
  LL_mDelay(2500);
  /* USER CODE END Init */

  /* Configure the system clock */
  SystemClock_Config();

  /* Initialize all configured peripherals */
  MX_GPIO_Init();
  MX_ADC1_Init();
  MX_DAC_Init();
  MX_TIM1_Init();
  MX_USART1_UART_Init();
  MX_MotorControl_Init();

  /* Initialize interrupts */
  MX_NVIC_Init();

  /* Infinite loop */
  while (1)
  {

  }
}

void SystemClock_Config(void)
{
  LL_FLASH_SetLatency(LL_FLASH_LATENCY_2);

   if(LL_FLASH_GetLatency() != LL_FLASH_LATENCY_2)
  {
  Error_Handler();
  }
  LL_RCC_HSI_Enable();

   /* Wait till HSI is ready */
  while(LL_RCC_HSI_IsReady() != 1)
  {

  }
  LL_RCC_HSI_SetCalibTrimming(16);
  LL_RCC_PLL_ConfigDomain_SYS(LL_RCC_PLLSOURCE_HSI_DIV_2, LL_RCC_PLL_MUL_16);
  LL_RCC_PLL_Enable();

   /* Wait till PLL is ready */
  while(LL_RCC_PLL_IsReady() != 1)
  {

  }
  LL_RCC_SetAHBPrescaler(LL_RCC_SYSCLK_DIV_1);
  LL_RCC_SetAPB1Prescaler(LL_RCC_APB1_DIV_2);
  LL_RCC_SetAPB2Prescaler(LL_RCC_APB1_DIV_1);
  LL_RCC_SetSysClkSource(LL_RCC_SYS_CLKSOURCE_PLL);

   /* Wait till System clock is ready */
  while(LL_RCC_GetSysClkSource() != LL_RCC_SYS_CLKSOURCE_STATUS_PLL)
  {

  }
  LL_SetSystemCoreClock(64000000);

   /* Update the time base */
  if (HAL_InitTick (TICK_INT_PRIORITY) != HAL_OK)
  {
    Error_Handler();
  };
  LL_RCC_SetUSARTClockSource(LL_RCC_USART1_CLKSOURCE_PCLK1);
  LL_RCC_SetTIMClockSource(LL_RCC_TIM1_CLKSOURCE_PCLK2);
}

/**
  * @brief NVIC Configuration.
  * @retval None
  */
static void MX_NVIC_Init(void)
{
  /* TIM1_BRK_TIM15_IRQn interrupt configuration */
  NVIC_SetPriority(TIM1_BRK_TIM15_IRQn, NVIC_EncodePriority(NVIC_GetPriorityGrouping(),4, 1));
  NVIC_EnableIRQ(TIM1_BRK_TIM15_IRQn);
  /* TIM1_UP_TIM16_IRQn interrupt configuration */
  NVIC_SetPriority(TIM1_UP_TIM16_IRQn, NVIC_EncodePriority(NVIC_GetPriorityGrouping(),0, 0));
  NVIC_EnableIRQ(TIM1_UP_TIM16_IRQn);
  /* ADC1_IRQn interrupt configuration */
  NVIC_SetPriority(ADC1_IRQn, NVIC_EncodePriority(NVIC_GetPriorityGrouping(),2, 0));
  NVIC_EnableIRQ(ADC1_IRQn);
  /* USART1_IRQn interrupt configuration */
  NVIC_SetPriority(USART1_IRQn, NVIC_EncodePriority(NVIC_GetPriorityGrouping(),3, 1));
  NVIC_EnableIRQ(USART1_IRQn);
}

static void MX_ADC1_Init(void)
{

  LL_ADC_InitTypeDef ADC_InitStruct = {0};
  LL_ADC_REG_InitTypeDef ADC_REG_InitStruct = {0};
  LL_ADC_CommonInitTypeDef ADC_CommonInitStruct = {0};
  LL_ADC_INJ_InitTypeDef ADC_INJ_InitStruct = {0};

  LL_GPIO_InitTypeDef GPIO_InitStruct = {0};

  /* Peripheral clock enable */
  LL_AHB1_GRP1_EnableClock(LL_AHB1_GRP1_PERIPH_ADC1);

  LL_AHB1_GRP1_EnableClock(LL_AHB1_GRP1_PERIPH_GPIOA);
  LL_AHB1_GRP1_EnableClock(LL_AHB1_GRP1_PERIPH_GPIOB);
  /**ADC1 GPIO Configuration
  PA0   ------> ADC1_IN1
  PA1   ------> ADC1_IN2
  PA6   ------> ADC1_IN10
  PB0   ------> ADC1_IN11
  */
  GPIO_InitStruct.Pin = M1_CURR_AMPL_U_Pin|M1_CURR_AMPL_V_Pin|M1_CURR_AMPL_W_Pin;
  GPIO_InitStruct.Mode = LL_GPIO_MODE_ANALOG;
  GPIO_InitStruct.Pull = LL_GPIO_PULL_NO;
  LL_GPIO_Init(GPIOA, &GPIO_InitStruct);

  GPIO_InitStruct.Pin = M1_BUS_VOLTAGE_Pin;
  GPIO_InitStruct.Mode = LL_GPIO_MODE_ANALOG;
  GPIO_InitStruct.Pull = LL_GPIO_PULL_NO;
  LL_GPIO_Init(M1_BUS_VOLTAGE_GPIO_Port, &GPIO_InitStruct);

  /** Common config
  */
  ADC_InitStruct.Resolution = LL_ADC_RESOLUTION_12B;
  ADC_InitStruct.DataAlignment = LL_ADC_DATA_ALIGN_LEFT;
  ADC_InitStruct.LowPowerMode = LL_ADC_LP_MODE_NONE;
  LL_ADC_Init(ADC1, &ADC_InitStruct);
  ADC_REG_InitStruct.TriggerSource = LL_ADC_REG_TRIG_SOFTWARE;
  ADC_REG_InitStruct.SequencerLength = LL_ADC_REG_SEQ_SCAN_DISABLE;
  ADC_REG_InitStruct.SequencerDiscont = LL_ADC_REG_SEQ_DISCONT_DISABLE;
  ADC_REG_InitStruct.ContinuousMode = LL_ADC_REG_CONV_SINGLE;
  ADC_REG_InitStruct.DMATransfer = LL_ADC_REG_DMA_TRANSFER_LIMITED;
  ADC_REG_InitStruct.Overrun = LL_ADC_REG_OVR_DATA_PRESERVED;
  LL_ADC_REG_Init(ADC1, &ADC_REG_InitStruct);
  LL_ADC_DisableIT_EOC(ADC1);
  LL_ADC_DisableIT_EOS(ADC1);
  ADC_CommonInitStruct.CommonClock = LL_ADC_CLOCK_SYNC_PCLK_DIV1;
  LL_ADC_CommonInit(__LL_ADC_COMMON_INSTANCE(ADC1), &ADC_CommonInitStruct);
  /** Configure Injected Channel
  */
  ADC_INJ_InitStruct.TriggerSource = LL_ADC_INJ_TRIG_EXT_TIM1_TRGO;
  ADC_INJ_InitStruct.SequencerLength = LL_ADC_INJ_SEQ_SCAN_ENABLE_3RANKS;
  ADC_INJ_InitStruct.SequencerDiscont = LL_ADC_INJ_SEQ_DISCONT_DISABLE;
  ADC_INJ_InitStruct.TrigAuto = LL_ADC_INJ_TRIG_INDEPENDENT;
  LL_ADC_INJ_Init(ADC1, &ADC_INJ_InitStruct);
  LL_ADC_INJ_SetQueueMode(ADC1, LL_ADC_INJ_QUEUE_2CONTEXTS_END_EMPTY);
  LL_ADC_DisableIT_JEOC(ADC1);
  LL_ADC_DisableIT_JEOS(ADC1);
  LL_ADC_INJ_SetSequencerRanks(ADC1, LL_ADC_INJ_RANK_1, LL_ADC_CHANNEL_1);
  LL_ADC_SetChannelSamplingTime(ADC1, LL_ADC_CHANNEL_1, LL_ADC_SAMPLINGTIME_19CYCLES_5);
  LL_ADC_SetChannelSingleDiff(ADC1, LL_ADC_CHANNEL_1, LL_ADC_SINGLE_ENDED);
  LL_ADC_INJ_SetTriggerEdge(ADC1, LL_ADC_INJ_TRIG_EXT_RISING);
  /** Configure Injected Channel
  */
  LL_ADC_INJ_Init(ADC1, &ADC_INJ_InitStruct);
  LL_ADC_INJ_SetQueueMode(ADC1, LL_ADC_INJ_QUEUE_2CONTEXTS_END_EMPTY);
  LL_ADC_DisableIT_JEOC(ADC1);
  LL_ADC_DisableIT_JEOS(ADC1);
  LL_ADC_INJ_SetSequencerRanks(ADC1, LL_ADC_INJ_RANK_2, LL_ADC_CHANNEL_2);
  LL_ADC_SetChannelSamplingTime(ADC1, LL_ADC_CHANNEL_2, LL_ADC_SAMPLINGTIME_19CYCLES_5);
  LL_ADC_SetChannelSingleDiff(ADC1, LL_ADC_CHANNEL_2, LL_ADC_SINGLE_ENDED);
  LL_ADC_INJ_SetTriggerEdge(ADC1, LL_ADC_INJ_TRIG_EXT_RISING);
  /** Configure Injected Channel
  */
  LL_ADC_INJ_Init(ADC1, &ADC_INJ_InitStruct);
  LL_ADC_INJ_SetQueueMode(ADC1, LL_ADC_INJ_QUEUE_2CONTEXTS_END_EMPTY);
  LL_ADC_DisableIT_JEOC(ADC1);
  LL_ADC_DisableIT_JEOS(ADC1);
  LL_ADC_INJ_SetSequencerRanks(ADC1, LL_ADC_INJ_RANK_3, LL_ADC_CHANNEL_10);
  LL_ADC_SetChannelSamplingTime(ADC1, LL_ADC_CHANNEL_10, LL_ADC_SAMPLINGTIME_19CYCLES_5);
  LL_ADC_SetChannelSingleDiff(ADC1, LL_ADC_CHANNEL_10, LL_ADC_SINGLE_ENDED);
  LL_ADC_INJ_SetTriggerEdge(ADC1, LL_ADC_INJ_TRIG_EXT_RISING);
  /** Configure Regular Channel
  */
  LL_ADC_REG_SetSequencerRanks(ADC1, LL_ADC_REG_RANK_1, LL_ADC_CHANNEL_11);
  LL_ADC_SetChannelSamplingTime(ADC1, LL_ADC_CHANNEL_11, LL_ADC_SAMPLINGTIME_61CYCLES_5);
  LL_ADC_SetChannelSingleDiff(ADC1, LL_ADC_CHANNEL_11, LL_ADC_SINGLE_ENDED);

}

static void MX_DAC_Init(void)
{

  LL_DAC_InitTypeDef DAC_InitStruct = {0};

  LL_GPIO_InitTypeDef GPIO_InitStruct = {0};

  /* Peripheral clock enable */
  LL_APB1_GRP1_EnableClock(LL_APB1_GRP1_PERIPH_DAC1);

  LL_AHB1_GRP1_EnableClock(LL_AHB1_GRP1_PERIPH_GPIOA);
  /**DAC GPIO Configuration
  PA4   ------> DAC_OUT1
  */
  GPIO_InitStruct.Pin = DBG_DAC_CH1_Pin;
  GPIO_InitStruct.Mode = LL_GPIO_MODE_ANALOG;
  GPIO_InitStruct.Pull = LL_GPIO_PULL_NO;
  LL_GPIO_Init(DBG_DAC_CH1_GPIO_Port, &GPIO_InitStruct);

  /** DAC channel OUT1 config
  */
  DAC_InitStruct.TriggerSource = LL_DAC_TRIG_SOFTWARE;
  DAC_InitStruct.WaveAutoGeneration = LL_DAC_WAVE_AUTO_GENERATION_NONE;
  DAC_InitStruct.OutputBuffer = LL_DAC_OUTPUT_BUFFER_DISABLE;
  LL_DAC_Init(DAC, LL_DAC_CHANNEL_1, &DAC_InitStruct);
  LL_DAC_EnableTrigger(DAC, LL_DAC_CHANNEL_1);

}

static void MX_TIM1_Init(void)
{

  LL_TIM_InitTypeDef TIM_InitStruct = {0};
  LL_TIM_OC_InitTypeDef TIM_OC_InitStruct = {0};
  LL_TIM_BDTR_InitTypeDef TIM_BDTRInitStruct = {0};

  LL_GPIO_InitTypeDef GPIO_InitStruct = {0};

  /* Peripheral clock enable */
  LL_APB2_GRP1_EnableClock(LL_APB2_GRP1_PERIPH_TIM1);

  LL_AHB1_GRP1_EnableClock(LL_AHB1_GRP1_PERIPH_GPIOA);
  /**TIM1 GPIO Configuration
  PA11   ------> TIM1_BKIN2
  */
  GPIO_InitStruct.Pin = M1_OCP_Pin;
  GPIO_InitStruct.Mode = LL_GPIO_MODE_ALTERNATE;
  GPIO_InitStruct.Speed = LL_GPIO_SPEED_FREQ_LOW;
  GPIO_InitStruct.OutputType = LL_GPIO_OUTPUT_PUSHPULL;
  GPIO_InitStruct.Pull = LL_GPIO_PULL_UP;
  GPIO_InitStruct.Alternate = LL_GPIO_AF_12;
  LL_GPIO_Init(M1_OCP_GPIO_Port, &GPIO_InitStruct);

  TIM_InitStruct.Prescaler = ((TIM_CLOCK_DIVIDER) - 1);
  TIM_InitStruct.CounterMode = LL_TIM_COUNTERMODE_CENTER_UP;
  TIM_InitStruct.Autoreload = ((PWM_PERIOD_CYCLES) / 2);
  TIM_InitStruct.ClockDivision = LL_TIM_CLOCKDIVISION_DIV2;
  TIM_InitStruct.RepetitionCounter = (REP_COUNTER);
  LL_TIM_Init(TIM1, &TIM_InitStruct);
  LL_TIM_DisableARRPreload(TIM1);
  LL_TIM_OC_EnablePreload(TIM1, LL_TIM_CHANNEL_CH1);
  TIM_OC_InitStruct.OCMode = LL_TIM_OCMODE_PWM1;
  TIM_OC_InitStruct.OCState = LL_TIM_OCSTATE_DISABLE;
  TIM_OC_InitStruct.OCNState = LL_TIM_OCSTATE_DISABLE;
  TIM_OC_InitStruct.CompareValue = 0;
  TIM_OC_InitStruct.OCPolarity = LL_TIM_OCPOLARITY_HIGH;
  TIM_OC_InitStruct.OCNPolarity = LL_TIM_OCPOLARITY_HIGH;
  TIM_OC_InitStruct.OCIdleState = LL_TIM_OCIDLESTATE_LOW;
  TIM_OC_InitStruct.OCNIdleState = LL_TIM_OCIDLESTATE_LOW;
  LL_TIM_OC_Init(TIM1, LL_TIM_CHANNEL_CH1, &TIM_OC_InitStruct);
  LL_TIM_OC_DisableFast(TIM1, LL_TIM_CHANNEL_CH1);
  LL_TIM_OC_EnablePreload(TIM1, LL_TIM_CHANNEL_CH2);
  TIM_OC_InitStruct.OCState = LL_TIM_OCSTATE_DISABLE;
  TIM_OC_InitStruct.OCNState = LL_TIM_OCSTATE_DISABLE;
  LL_TIM_OC_Init(TIM1, LL_TIM_CHANNEL_CH2, &TIM_OC_InitStruct);
  LL_TIM_OC_DisableFast(TIM1, LL_TIM_CHANNEL_CH2);
  LL_TIM_OC_EnablePreload(TIM1, LL_TIM_CHANNEL_CH3);
  TIM_OC_InitStruct.OCState = LL_TIM_OCSTATE_DISABLE;
  TIM_OC_InitStruct.OCNState = LL_TIM_OCSTATE_DISABLE;
  LL_TIM_OC_Init(TIM1, LL_TIM_CHANNEL_CH3, &TIM_OC_InitStruct);
  LL_TIM_OC_DisableFast(TIM1, LL_TIM_CHANNEL_CH3);
  LL_TIM_OC_EnablePreload(TIM1, LL_TIM_CHANNEL_CH4);
  TIM_OC_InitStruct.OCMode = LL_TIM_OCMODE_PWM2;
  TIM_OC_InitStruct.OCState = LL_TIM_OCSTATE_DISABLE;
  TIM_OC_InitStruct.OCNState = LL_TIM_OCSTATE_DISABLE;
  TIM_OC_InitStruct.CompareValue = (((PWM_PERIOD_CYCLES) / 2) - (HTMIN));
  LL_TIM_OC_Init(TIM1, LL_TIM_CHANNEL_CH4, &TIM_OC_InitStruct);
  LL_TIM_OC_DisableFast(TIM1, LL_TIM_CHANNEL_CH4);
  LL_TIM_SetTriggerInput(TIM1, LL_TIM_TS_ITR1);
  LL_TIM_SetSlaveMode(TIM1, LL_TIM_SLAVEMODE_TRIGGER);
  LL_TIM_DisableIT_TRIG(TIM1);
  LL_TIM_DisableDMAReq_TRIG(TIM1);
  LL_TIM_SetTriggerOutput(TIM1, LL_TIM_TRGO_OC4REF);
  LL_TIM_SetTriggerOutput2(TIM1, LL_TIM_TRGO2_RESET);
  LL_TIM_DisableMasterSlaveMode(TIM1);
  TIM_BDTRInitStruct.OSSRState = LL_TIM_OSSR_ENABLE;
  TIM_BDTRInitStruct.OSSIState = LL_TIM_OSSI_ENABLE;
  TIM_BDTRInitStruct.LockLevel = LL_TIM_LOCKLEVEL_1;
  TIM_BDTRInitStruct.DeadTime = ((DEAD_TIME_COUNTS) / 2);
  TIM_BDTRInitStruct.BreakState = LL_TIM_BREAK_DISABLE;
  TIM_BDTRInitStruct.BreakPolarity = LL_TIM_BREAK_POLARITY_HIGH;
  TIM_BDTRInitStruct.BreakFilter = LL_TIM_BREAK_FILTER_FDIV1;
  TIM_BDTRInitStruct.Break2State = LL_TIM_BREAK2_ENABLE;
  TIM_BDTRInitStruct.Break2Polarity = LL_TIM_BREAK2_POLARITY_LOW;
  TIM_BDTRInitStruct.Break2Filter = LL_TIM_BREAK2_FILTER_FDIV1;
  TIM_BDTRInitStruct.AutomaticOutput = LL_TIM_AUTOMATICOUTPUT_DISABLE;
  LL_TIM_BDTR_Init(TIM1, &TIM_BDTRInitStruct);
  LL_AHB1_GRP1_EnableClock(LL_AHB1_GRP1_PERIPH_GPIOB);
  LL_AHB1_GRP1_EnableClock(LL_AHB1_GRP1_PERIPH_GPIOA);
  /**TIM1 GPIO Configuration
  PB13   ------> TIM1_CH1N
  PB14   ------> TIM1_CH2N
  PB15   ------> TIM1_CH3N
  PA8   ------> TIM1_CH1
  PA9   ------> TIM1_CH2
  PA10   ------> TIM1_CH3
  */
  GPIO_InitStruct.Pin = M1_PWM_UL_Pin|M1_PWM_VL_Pin;
  GPIO_InitStruct.Mode = LL_GPIO_MODE_ALTERNATE;
  GPIO_InitStruct.Speed = LL_GPIO_SPEED_FREQ_HIGH;
  GPIO_InitStruct.OutputType = LL_GPIO_OUTPUT_PUSHPULL;
  GPIO_InitStruct.Pull = LL_GPIO_PULL_DOWN;
  GPIO_InitStruct.Alternate = LL_GPIO_AF_6;
  LL_GPIO_Init(GPIOB, &GPIO_InitStruct);

  GPIO_InitStruct.Pin = M1_PWM_WL_Pin;
  GPIO_InitStruct.Mode = LL_GPIO_MODE_ALTERNATE;
  GPIO_InitStruct.Speed = LL_GPIO_SPEED_FREQ_HIGH;
  GPIO_InitStruct.OutputType = LL_GPIO_OUTPUT_PUSHPULL;
  GPIO_InitStruct.Pull = LL_GPIO_PULL_DOWN;
  GPIO_InitStruct.Alternate = LL_GPIO_AF_4;
  LL_GPIO_Init(M1_PWM_WL_GPIO_Port, &GPIO_InitStruct);

  GPIO_InitStruct.Pin = M1_PWM_UH_Pin|M1_PWM_VH_Pin|M1_PWM_WH_Pin;
  GPIO_InitStruct.Mode = LL_GPIO_MODE_ALTERNATE;
  GPIO_InitStruct.Speed = LL_GPIO_SPEED_FREQ_HIGH;
  GPIO_InitStruct.OutputType = LL_GPIO_OUTPUT_PUSHPULL;
  GPIO_InitStruct.Pull = LL_GPIO_PULL_DOWN;
  GPIO_InitStruct.Alternate = LL_GPIO_AF_6;
  LL_GPIO_Init(GPIOA, &GPIO_InitStruct);

}

static void MX_USART1_UART_Init(void)
{

  LL_USART_InitTypeDef USART_InitStruct = {0};

  LL_GPIO_InitTypeDef GPIO_InitStruct = {0};

  /* Peripheral clock enable */
  LL_APB2_GRP1_EnableClock(LL_APB2_GRP1_PERIPH_USART1);

  LL_AHB1_GRP1_EnableClock(LL_AHB1_GRP1_PERIPH_GPIOB);
  /**USART1 GPIO Configuration
  PB6   ------> USART1_TX
  PB7   ------> USART1_RX
  */
  GPIO_InitStruct.Pin = UART_TX_Pin|UART_RX_Pin;
  GPIO_InitStruct.Mode = LL_GPIO_MODE_ALTERNATE;
  GPIO_InitStruct.Speed = LL_GPIO_SPEED_FREQ_LOW;
  GPIO_InitStruct.OutputType = LL_GPIO_OUTPUT_PUSHPULL;
  GPIO_InitStruct.Pull = LL_GPIO_PULL_NO;
  GPIO_InitStruct.Alternate = LL_GPIO_AF_7;
  LL_GPIO_Init(GPIOB, &GPIO_InitStruct);

  USART_InitStruct.BaudRate = 115200;
  USART_InitStruct.DataWidth = LL_USART_DATAWIDTH_8B;
  USART_InitStruct.StopBits = LL_USART_STOPBITS_1;
  USART_InitStruct.Parity = LL_USART_PARITY_NONE;
  USART_InitStruct.TransferDirection = LL_USART_DIRECTION_TX_RX;
  USART_InitStruct.HardwareFlowControl = LL_USART_HWCONTROL_NONE;
  USART_InitStruct.OverSampling = LL_USART_OVERSAMPLING_16;
  LL_USART_Init(USART1, &USART_InitStruct);
  LL_USART_DisableIT_CTS(USART1);
  LL_USART_ConfigAsyncMode(USART1);
  LL_USART_Enable(USART1);

}

static void MX_GPIO_Init(void)
{

  /* GPIO Ports Clock Enable */
  LL_AHB1_GRP1_EnableClock(LL_AHB1_GRP1_PERIPH_GPIOA);
  LL_AHB1_GRP1_EnableClock(LL_AHB1_GRP1_PERIPH_GPIOB);

}

void Error_Handler(void)
{
}

/************************ (C) COPYRIGHT STMicroelectronics *****END OF FILE****/
